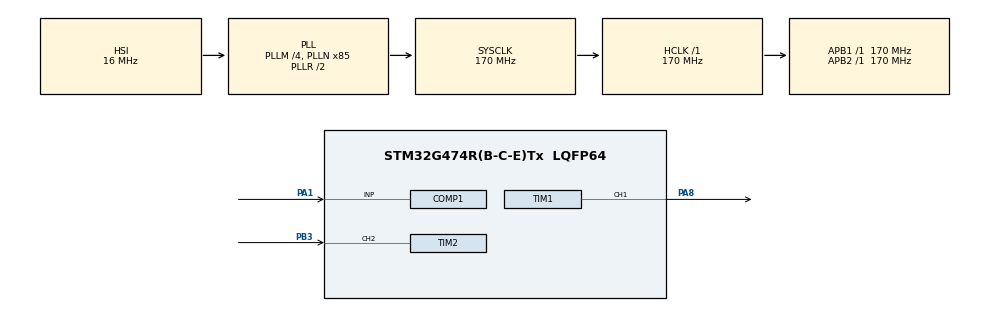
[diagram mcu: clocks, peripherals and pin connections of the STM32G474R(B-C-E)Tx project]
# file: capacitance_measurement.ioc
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Mcu.Family=STM32G4
Mcu.Name=STM32G474R(B-C-E)Tx
Mcu.Package=LQFP64
NVIC.PriorityGroup=NVIC_PRIORITYGROUP_4
NVIC.TIM2_IRQn=true\:0\:0\:false\:false\:true\:true\:true\:true
PA1.Mode=INP
PA1.Signal=COMP1_INP
PA2.TagName=VCP_TX
PA3.TagName=VCP_RX
PA5.TagName=LD2
PA8.Signal=S_TIM1_CH1
PB3.Signal=S_TIM2_CH2
PC13.TagName=B1
ProjectManager.HeapSize=0x200
ProjectManager.StackSize=0x400
ProjectManager.TargetToolchain=STM32CubeIDE
RCC.ADC12Freq_Value=170000000
RCC.ADC345Freq_Value=170000000
RCC.AHBFreq_Value=170000000
RCC.APB1Freq_Value=170000000
RCC.APB1TimFreq_Value=170000000
RCC.APB2Freq_Value=170000000
RCC.APB2TimFreq_Value=170000000
RCC.CortexFreq_Value=170000000
RCC.EXTERNAL_CLOCK_VALUE=12288000
RCC.HCLKFreq_Value=170000000
RCC.HSE_VALUE=24000000
RCC.HSI48_VALUE=48000000
RCC.HSI_VALUE=16000000
RCC.LSE_VALUE=32768
RCC.PLLM=RCC_PLLM_DIV4
RCC.PLLN=85
RCC.RTCClockSelection=RCC_RTCCLKSOURCE_LSE
RCC.SYSCLKFreq_VALUE=170000000
RCC.SYSCLKSource=RCC_SYSCLKSOURCE_PLLCLK
RCC.USBFreq_Value=170000000
RCC.VCOOutputFreq_Value=340000000
SH.S_TIM1_CH1.0=TIM1_CH1,PWM Generation1 CH1
SH.S_TIM2_CH2.0=TIM2_CH2,Input_Capture2_from_TI2
SH.S_TIM2_CH2.1=TIM2_CH2,TriggerSource_TI2FP2
TIM1.Channel-PWM\ Generation1\ CH1=TIM_CHANNEL_1
TIM1.PeriodNoDither=1000-1
TIM1.Prescaler=850-1
TIM1.PulseNoDither_1=500-1
TIM2.Channel-Input_Capture1_from_TI1_REMAP_TIM2=TIM_CHANNEL_1
TIM2.Channel-Input_Capture2_from_TI2=TIM_CHANNEL_2
TIM2.ICFilter_CH1=0xF
TIM2.ICFilter_CH2=0xF
VP_COMP1_VS_DAC1OUT1.Mode=INM_DAC1OUT1
VP_DAC1_VS_DACI1.Mode=DAC_OUT1_Int
VP_SYS_VS_DBSignals.Mode=DisableDeadBatterySignals
VP_TIM1_VS_ClockSourceINT.Mode=Internal
VP_TIM2_VS_ClockSourceINT.Mode=Internal
VP_TIM2_VS_ControllerModeReset.Mode=Reset Mode
VP_TIM2_VS_NoInput1.Mode=Input_Capture1_from_TI1_REMAP_TIM2
board=NUCLEO-G474RE

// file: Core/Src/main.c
/* USER CODE BEGIN Header */
/**
  ******************************************************************************
  * @file           : main.c
  * @brief          : Main program body
  ******************************************************************************
  * @attention
  *
  * Copyright (c) 2026 STMicroelectronics.
  * All rights reserved.
  *
  * This software is licensed under terms that can be found in the LICENSE file
  * in the root directory of this software component.
  * If no LICENSE file comes with this software, it is provided AS-IS.
  *
  ******************************************************************************
  */
/* USER CODE END Header */
#include "main.h"

COMP_HandleTypeDef hcomp1;

DAC_HandleTypeDef hdac1;

TIM_HandleTypeDef htim1;
TIM_HandleTypeDef htim2;

/* USER CODE BEGIN PV */
float C_nF;

/* USER CODE END PV */

void SystemClock_Config(void);
static void MX_GPIO_Init(void);
static void MX_COMP1_Init(void);
static void MX_DAC1_Init(void);
static void MX_TIM1_Init(void);
static void MX_TIM2_Init(void);

/* USER CODE BEGIN 0 */
#define R_VALUE     470.0f
#define LN2         0.693147f

volatile uint32_t t_delay = 0;
volatile uint8_t new_measurement = 0;
#define TIM2_CLK_HZ 170000000.0f
/* USER CODE END 0 */

int main(void)
{

  /* MCU Configuration--------------------------------------------------------*/

  /* Reset of all peripherals, Initializes the Flash interface and the Systick. */
  HAL_Init();

  /* Configure the system clock */
  SystemClock_Config();

  /* Initialize all configured peripherals */
  MX_GPIO_Init();
  MX_COMP1_Init();
  MX_DAC1_Init();
  MX_TIM1_Init();
  MX_TIM2_Init();
  /* USER CODE BEGIN 2 */
  HAL_DAC_SetValue(&hdac1, DAC_CHANNEL_1, DAC_ALIGN_12B_R, 1985);
  HAL_DAC_Start(&hdac1, DAC_CHANNEL_1);

  HAL_COMP_Start(&hcomp1);

  HAL_TIM_PWM_Start(&htim1, TIM_CHANNEL_1);

  HAL_TIM_IC_Start_IT(&htim2, TIM_CHANNEL_1);
  /* USER CODE END 2 */

  /* Infinite loop */
  /* USER CODE BEGIN WHILE */
  while (1)
  {

	  if(new_measurement)
	  {
	      new_measurement = 0;

	      float Td = t_delay / TIM2_CLK_HZ;

	      float C = Td / (R_VALUE * LN2);

	      C_nF = C * 1e9f;
	  }
    /* USER CODE END WHILE */

  }
}

void SystemClock_Config(void)
{
  RCC_OscInitTypeDef RCC_OscInitStruct = {0};
  RCC_ClkInitTypeDef RCC_ClkInitStruct = {0};

  /** Configure the main internal regulator output voltage
  */
  HAL_PWREx_ControlVoltageScaling(PWR_REGULATOR_VOLTAGE_SCALE1_BOOST);

  /** Initializes the RCC Oscillators according to the specified parameters
  * in the RCC_OscInitTypeDef structure.
  */
  RCC_OscInitStruct.OscillatorType = RCC_OSCILLATORTYPE_HSI;
  RCC_OscInitStruct.HSIState = RCC_HSI_ON;
  RCC_OscInitStruct.HSICalibrationValue = RCC_HSICALIBRATION_DEFAULT;
  RCC_OscInitStruct.PLL.PLLState = RCC_PLL_ON;
  RCC_OscInitStruct.PLL.PLLSource = RCC_PLLSOURCE_HSI;
  RCC_OscInitStruct.PLL.PLLM = RCC_PLLM_DIV4;
  RCC_OscInitStruct.PLL.PLLN = 85;
  RCC_OscInitStruct.PLL.PLLP = RCC_PLLP_DIV2;
  RCC_OscInitStruct.PLL.PLLQ = RCC_PLLQ_DIV2;
  RCC_OscInitStruct.PLL.PLLR = RCC_PLLR_DIV2;
  if (HAL_RCC_OscConfig(&RCC_OscInitStruct) != HAL_OK)
  {
    Error_Handler();
  }

  /** Initializes the CPU, AHB and APB buses clocks
  */
  RCC_ClkInitStruct.ClockType = RCC_CLOCKTYPE_HCLK|RCC_CLOCKTYPE_SYSCLK
                              |RCC_CLOCKTYPE_PCLK1|RCC_CLOCKTYPE_PCLK2;
  RCC_ClkInitStruct.SYSCLKSource = RCC_SYSCLKSOURCE_PLLCLK;
  RCC_ClkInitStruct.AHBCLKDivider = RCC_SYSCLK_DIV1;
  RCC_ClkInitStruct.APB1CLKDivider = RCC_HCLK_DIV1;
  RCC_ClkInitStruct.APB2CLKDivider = RCC_HCLK_DIV1;

  if (HAL_RCC_ClockConfig(&RCC_ClkInitStruct, FLASH_LATENCY_4) != HAL_OK)
  {
    Error_Handler();
  }
}

static void MX_COMP1_Init(void)
{

  hcomp1.Instance = COMP1;
  hcomp1.Init.InputPlus = COMP_INPUT_PLUS_IO1;
  hcomp1.Init.InputMinus = COMP_INPUT_MINUS_DAC1_CH1;
  hcomp1.Init.OutputPol = COMP_OUTPUTPOL_NONINVERTED;
  hcomp1.Init.Hysteresis = COMP_HYSTERESIS_NONE;
  hcomp1.Init.BlankingSrce = COMP_BLANKINGSRC_NONE;
  hcomp1.Init.TriggerMode = COMP_TRIGGERMODE_NONE;
  if (HAL_COMP_Init(&hcomp1) != HAL_OK)
  {
    Error_Handler();
  }

}

static void MX_DAC1_Init(void)
{

  DAC_ChannelConfTypeDef sConfig = {0};

  /** DAC Initialization
  */
  hdac1.Instance = DAC1;
  if (HAL_DAC_Init(&hdac1) != HAL_OK)
  {
    Error_Handler();
  }

  /** DAC channel OUT1 config
  */
  sConfig.DAC_HighFrequency = DAC_HIGH_FREQUENCY_INTERFACE_MODE_AUTOMATIC;
  sConfig.DAC_DMADoubleDataMode = DISABLE;
  sConfig.DAC_SignedFormat = DISABLE;
  sConfig.DAC_SampleAndHold = DAC_SAMPLEANDHOLD_DISABLE;
  sConfig.DAC_Trigger = DAC_TRIGGER_NONE;
  sConfig.DAC_Trigger2 = DAC_TRIGGER_NONE;
  sConfig.DAC_OutputBuffer = DAC_OUTPUTBUFFER_DISABLE;
  sConfig.DAC_ConnectOnChipPeripheral = DAC_CHIPCONNECT_INTERNAL;
  sConfig.DAC_UserTrimming = DAC_TRIMMING_FACTORY;
  if (HAL_DAC_ConfigChannel(&hdac1, &sConfig, DAC_CHANNEL_1) != HAL_OK)
  {
    Error_Handler();
  }

}

static void MX_TIM1_Init(void)
{

  TIM_ClockConfigTypeDef sClockSourceConfig = {0};
  TIM_MasterConfigTypeDef sMasterConfig = {0};
  TIM_OC_InitTypeDef sConfigOC = {0};
  TIM_BreakDeadTimeConfigTypeDef sBreakDeadTimeConfig = {0};

  htim1.Instance = TIM1;
  htim1.Init.Prescaler = 850-1;
  htim1.Init.CounterMode = TIM_COUNTERMODE_UP;
  htim1.Init.Period = 999;
  htim1.Init.ClockDivision = TIM_CLOCKDIVISION_DIV1;
  htim1.Init.RepetitionCounter = 0;
  htim1.Init.AutoReloadPreload = TIM_AUTORELOAD_PRELOAD_DISABLE;
  if (HAL_TIM_Base_Init(&htim1) != HAL_OK)
  {
    Error_Handler();
  }
  sClockSourceConfig.ClockSource = TIM_CLOCKSOURCE_INTERNAL;
  if (HAL_TIM_ConfigClockSource(&htim1, &sClockSourceConfig) != HAL_OK)
  {
    Error_Handler();
  }
  if (HAL_TIM_PWM_Init(&htim1) != HAL_OK)
  {
    Error_Handler();
  }
  sMasterConfig.MasterOutputTrigger = TIM_TRGO_RESET;
  sMasterConfig.MasterOutputTrigger2 = TIM_TRGO2_RESET;
  sMasterConfig.MasterSlaveMode = TIM_MASTERSLAVEMODE_DISABLE;
  if (HAL_TIMEx_MasterConfigSynchronization(&htim1, &sMasterConfig) != HAL_OK)
  {
    Error_Handler();
  }
  sConfigOC.OCMode = TIM_OCMODE_PWM1;
  sConfigOC.Pulse = 499;
  sConfigOC.OCPolarity = TIM_OCPOLARITY_HIGH;
  sConfigOC.OCNPolarity = TIM_OCNPOLARITY_HIGH;
  sConfigOC.OCFastMode = TIM_OCFAST_DISABLE;
  sConfigOC.OCIdleState = TIM_OCIDLESTATE_RESET;
  sConfigOC.OCNIdleState = TIM_OCNIDLESTATE_RESET;
  if (HAL_TIM_PWM_ConfigChannel(&htim1, &sConfigOC, TIM_CHANNEL_1) != HAL_OK)
  {
    Error_Handler();
  }
  sBreakDeadTimeConfig.OffStateRunMode = TIM_OSSR_DISABLE;
  sBreakDeadTimeConfig.OffStateIDLEMode = TIM_OSSI_DISABLE;
  sBreakDeadTimeConfig.LockLevel = TIM_LOCKLEVEL_OFF;
  sBreakDeadTimeConfig.DeadTime = 0;
  sBreakDeadTimeConfig.BreakState = TIM_BREAK_DISABLE;
  sBreakDeadTimeConfig.BreakPolarity = TIM_BREAKPOLARITY_HIGH;
  sBreakDeadTimeConfig.BreakFilter = 0;
  sBreakDeadTimeConfig.BreakAFMode = TIM_BREAK_AFMODE_INPUT;
  sBreakDeadTimeConfig.Break2State = TIM_BREAK2_DISABLE;
  sBreakDeadTimeConfig.Break2Polarity = TIM_BREAK2POLARITY_HIGH;
  sBreakDeadTimeConfig.Break2Filter = 0;
  sBreakDeadTimeConfig.Break2AFMode = TIM_BREAK_AFMODE_INPUT;
  sBreakDeadTimeConfig.AutomaticOutput = TIM_AUTOMATICOUTPUT_DISABLE;
  if (HAL_TIMEx_ConfigBreakDeadTime(&htim1, &sBreakDeadTimeConfig) != HAL_OK)
  {
    Error_Handler();
  }
  HAL_TIM_MspPostInit(&htim1);

}

static void MX_TIM2_Init(void)
{

  TIM_ClockConfigTypeDef sClockSourceConfig = {0};
  TIM_SlaveConfigTypeDef sSlaveConfig = {0};
  TIM_MasterConfigTypeDef sMasterConfig = {0};
  TIM_IC_InitTypeDef sConfigIC = {0};

  htim2.Instance = TIM2;
  htim2.Init.Prescaler = 0;
  htim2.Init.CounterMode = TIM_COUNTERMODE_UP;
  htim2.Init.Period = 4294967295;
  htim2.Init.ClockDivision = TIM_CLOCKDIVISION_DIV1;
  htim2.Init.AutoReloadPreload = TIM_AUTORELOAD_PRELOAD_DISABLE;
  if (HAL_TIM_Base_Init(&htim2) != HAL_OK)
  {
    Error_Handler();
  }
  sClockSourceConfig.ClockSource = TIM_CLOCKSOURCE_INTERNAL;
  if (HAL_TIM_ConfigClockSource(&htim2, &sClockSourceConfig) != HAL_OK)
  {
    Error_Handler();
  }
  if (HAL_TIM_IC_Init(&htim2) != HAL_OK)
  {
    Error_Handler();
  }
  sSlaveConfig.SlaveMode = TIM_SLAVEMODE_RESET;
  sSlaveConfig.InputTrigger = TIM_TS_TI2FP2;
  sSlaveConfig.TriggerPolarity = TIM_INPUTCHANNELPOLARITY_RISING;
  sSlaveConfig.TriggerFilter = 0;
  if (HAL_TIM_SlaveConfigSynchro(&htim2, &sSlaveConfig) != HAL_OK)
  {
    Error_Handler();
  }
  sMasterConfig.MasterOutputTrigger = TIM_TRGO_RESET;
  sMasterConfig.MasterSlaveMode = TIM_MASTERSLAVEMODE_DISABLE;
  if (HAL_TIMEx_MasterConfigSynchronization(&htim2, &sMasterConfig) != HAL_OK)
  {
    Error_Handler();
  }
  sConfigIC.ICPolarity = TIM_INPUTCHANNELPOLARITY_RISING;
  sConfigIC.ICSelection = TIM_ICSELECTION_DIRECTTI;
  sConfigIC.ICPrescaler = TIM_ICPSC_DIV1;
  sConfigIC.ICFilter = 0xF;
  if (HAL_TIM_IC_ConfigChannel(&htim2, &sConfigIC, TIM_CHANNEL_1) != HAL_OK)
  {
    Error_Handler();
  }
  if (HAL_TIMEx_TISelection(&htim2, TIM_TIM2_TI1_COMP1, TIM_CHANNEL_1) != HAL_OK)
  {
    Error_Handler();
  }
  if (HAL_TIM_IC_ConfigChannel(&htim2, &sConfigIC, TIM_CHANNEL_2) != HAL_OK)
  {
    Error_Handler();
  }

}

static void MX_GPIO_Init(void)
{

  /* GPIO Ports Clock Enable */
  __HAL_RCC_GPIOA_CLK_ENABLE();
  __HAL_RCC_GPIOB_CLK_ENABLE();

}

/* USER CODE BEGIN 4 */
void HAL_TIM_IC_CaptureCallback(TIM_HandleTypeDef *htim)
{
    if(htim->Instance == TIM2)
    {
        if(htim->Channel == HAL_TIM_ACTIVE_CHANNEL_1)
        {
            t_delay = HAL_TIM_ReadCapturedValue(htim, TIM_CHANNEL_1);
            new_measurement = 1;
        }
    }
}
/* USER CODE END 4 */

void Error_Handler(void)
{
  __disable_irq();
  while (1)
  {
  }
}
